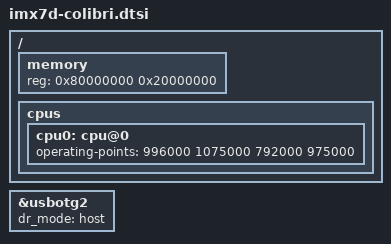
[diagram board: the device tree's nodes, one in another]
/*
 * Copyright (C) 2016-2017 Toradex AG
 *
 * This program is free software; you can redistribute it and/or modify
 * it under the terms of the GNU General Public License version 2 as
 * published by the Free Software Foundation.
 */

#include "imx7d.dtsi"
#include "imx7-colibri.dtsi"

/ {
	memory {
		reg = <0x80000000 0x20000000>;
	};

	cpus {
		cpu0: cpu@0 {
			operating-points = <
				/* KHz	uV */
				996000	1075000
				792000	975000
			>;
		};
	};
};

&usbotg2 {
	dr_mode = "host";
};
